VERSION ""

BS_:

BU_: BITSET

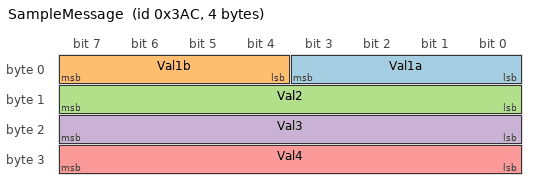
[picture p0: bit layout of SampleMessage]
BO_ 940 SampleMessage: 4 BITSET
    SG_ Val1a : 0|4@1+ (1,0) [0|1] "unitless" BITSET
    SG_ Val1b : 4|4@1+ (1,0) [0|1] "unitless" BITSET
    SG_ Val2 : 8|8@1+ (1,0) [0|1] "unitless" BITSET
    SG_ Val3 : 16|8@1+ (1,0) [0|1] "unitless" BITSET
    SG_ Val4 : 24|8@1+ (1,0) [0|1] "unitless" BITSET
